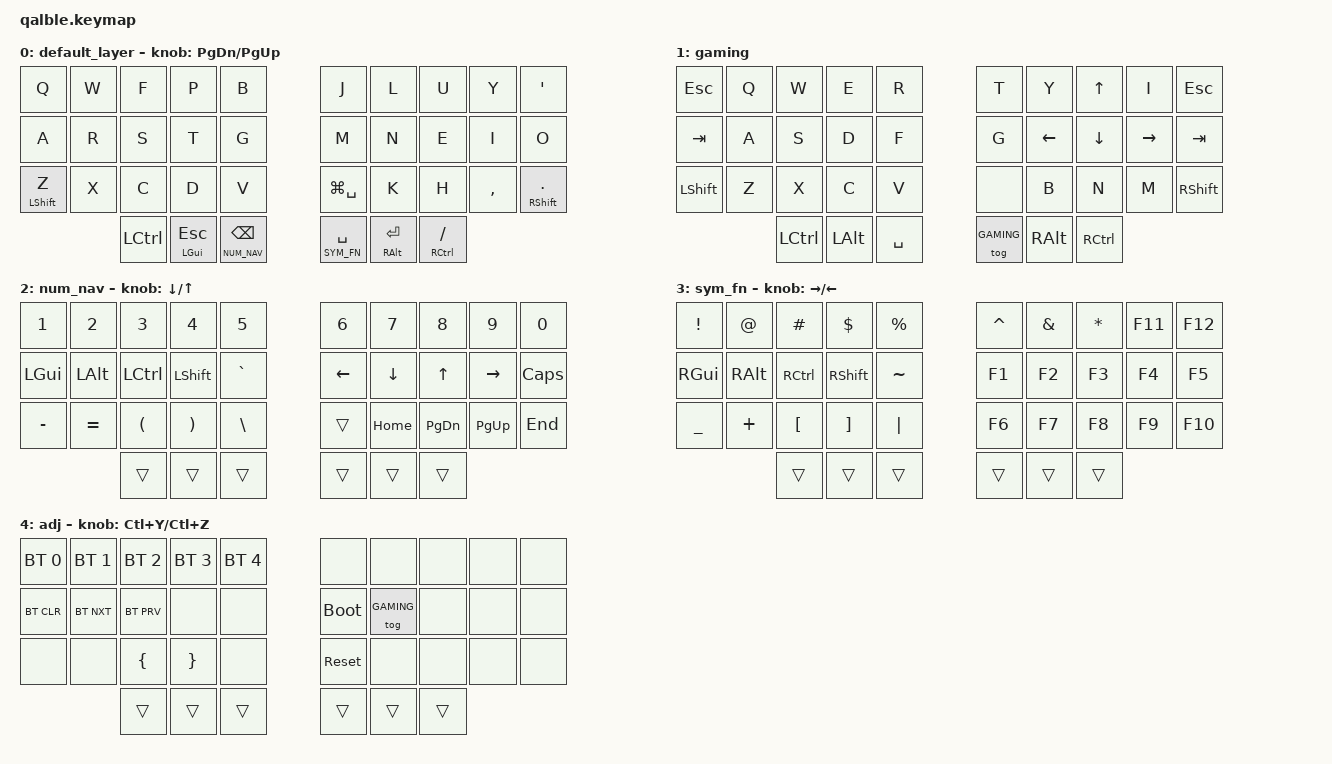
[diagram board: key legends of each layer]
#include <behaviors.dtsi>
#include <dt-bindings/zmk/keys.h>
#include <dt-bindings/zmk/bt.h>

#define DEFAULT 0
#define GAMING  1
#define NUM_NAV 2
#define SYM_FN  3
#define ADJ     4

/ {
    combos {
        /* Key positions
             0   1   2   3   4     5   6   7   8   9
            10  11  12  13  14    15  16  17  18  19
            20  21  22  23  24    25  26  27  28  29
            30      31      32    33      34      35 
        */
        
        compatible = "zmk,combos";
        
        #define COMBO(NAME, BINDINGS, KEYPOS) \
          combo_##NAME { \
            bindings = <BINDINGS>; \
            key-positions = <KEYPOS>; \
            layers = <0 2 3 4>; \
          };
        
        COMBO(clkCaps,   &kp CAPS,     7  21  26)
        COMBO(wfEsc,     &kp ESC,      1   2)
        COMBO(fpTab,     &kp TAB,      2   3)
        COMBO(luDel,     &kp DEL,      6   7)
        COMBO(uyBspc,    &kp BSPC,     7   8)
        COMBO(yQuotScln, &kp SEMI,     8   9)
        COMBO(khCol,     &kp COLON,   26  27)
        COMBO(hCommEnt,  &kp RET,     27  28)
    };

    conditional_layers {
        compatible = "zmk,conditional-layers";
        tri_layer {
            if-layers = <2 3>;
            then-layer = <4>;
        };
    };

    behaviors {
        mtp: mod_tap_preferred {
            compatible = "zmk,behavior-hold-tap";
            label = "MOD_TAP_PREFERRED";
            #binding-cells = <2>;
            tapping-term-ms = <200>;
            flavor = "tap-preferred";
            bindings = <&kp>, <&kp>;
        };
    };

    keymap {
        compatible = "zmk,keymap";

        default_layer {
            bindings = <
    &kp Q          &kp W      &kp F       &kp P        &kp B             &kp J          &kp L    &kp U       &kp Y      &kp SQT
    &kp A          &kp R      &kp S       &kp T        &kp G             &kp M          &kp N    &kp E       &kp I      &kp O
    &mtp LSHFT Z   &kp X      &kp C       &kp D        &kp V             &kp LG(SPACE)  &kp K    &kp H       &kp COMMA  &mtp RSHFT DOT
    &kp LCTRL                 &mtp LGUI ESC            &lt NUM_NAV BSPC  &lt SYM_FN SPACE        &mtp RALT RET          &mtp RCTRL FSLH
            >;
            sensor-bindings = <&inc_dec_kp PG_DN PG_UP>;
        };

        gaming {
            bindings = <
    &kp ESC    &kp Q   &kp W      &kp E   &kp R                     &kp T         &kp Y      &kp UP     &kp I       &kp ESC    
    &kp TAB    &kp A   &kp S      &kp D   &kp F                     &kp G         &kp LEFT   &kp DOWN   &kp RIGHT   &kp TAB    
    &kp LSHFT  &kp Z   &kp X      &kp C   &kp V                     &none         &kp B      &kp N      &kp M       &kp RSHFT
    &kp LCTRL          &kp LALT           &kp SPACE                 &tog GAMING              &kp RALT               &kp RCTRL
            >;
        };


        num_nav {
            bindings = <
    &kp N1     &kp N2     &kp N3     &kp N4     &kp N5              &kp N6     &kp N7       &kp N8      &kp N9       &kp N0
    &kp LGUI   &kp LALT   &kp LCTRL  &kp LSHFT  &kp GRAVE           &kp LEFT   &kp DOWN     &kp UP      &kp RIGHT    &kp CAPS
    &kp MINUS  &kp EQUAL  &kp LPAR   &kp RPAR   &kp BSLH            &trans     &kp HOME     &kp PG_DN   &kp PG_UP    &kp END
    &trans                &trans                &trans              &trans                  &trans                   &trans
            >;
            sensor-bindings = <&inc_dec_kp DOWN UP>;
        };

        sym_fn {
            bindings = <
    &kp EXCL    &kp AT     &kp HASH   &kp DLLR    &kp PRCNT          &kp CARET   &kp AMPS    &kp ASTRK   &kp F11    &kp F12
    &kp RGUI    &kp RALT   &kp RCTRL  &kp RSHFT   &kp TILDE          &kp F1      &kp F2      &kp F3      &kp F4     &kp F5
    &kp UNDER   &kp PLUS   &kp LBKT   &kp RBKT    &kp PIPE           &kp F6      &kp F7      &kp F8      &kp F9     &kp F10
    &trans                 &trans                 &trans             &trans                  &trans                 &trans
            >;
            sensor-bindings = <&inc_dec_kp RIGHT LEFT>;
        };

        adj {
            bindings = <
    &bt BT_SEL 0  &bt BT_SEL 1  &bt BT_SEL 2  &bt BT_SEL 3  &bt BT_SEL 4          &none         &none         &none   &none   &none
    &bt BT_CLR    &bt BT_NXT    &bt BT_PRV    &none         &none                 &bootloader   &tog GAMING   &none   &none   &none
    &none         &none         &kp LBRC      &kp RBRC      &none                 &sys_reset    &none         &none   &none   &none
    &trans                      &trans                      &trans                &trans                      &trans          &trans
            >;
            sensor-bindings = <&inc_dec_kp LC(Y) LC(Z)>;
        };
    };
};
